# AE8SUPERSET_CM55_HP_View register map
Vendor: Alif Semiconductor; Series: E8; File version: 1.0
CPU: CM55 r1p0, selectable endian, MPU, FPU, double-precision FPU, DSP, VTOR, 8 interrupt priority bits, 1 SAU regions
Registers are 32-bit, read-write, reset 0x0 unless marked. A register's access mark holds for its fields unless they carry their own. Offsets are from the block's base; [hi:lo] are bit positions; lines under a group give offsets from that group; {n}, {i} and the like mark numbered series.

## PINMUX
Base 0x1A603000
{0x0+0x20*i} PINMUX_CFG[{i}] (i=0..17) group
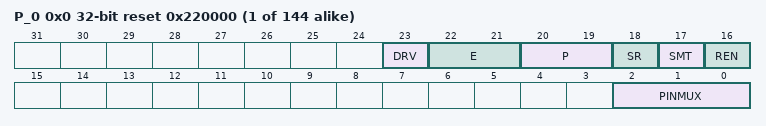
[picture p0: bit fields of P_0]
  {0x0+4j} P_{j} reset 0x220000 (j=0..7) — Control Register for Port n, Pin {j}
    [23] DRV — Driver type
      0=Push-pull; 1=Open drain
    [22:21] E — Output drive strength NOTE: Reset value is 0x3 (12 mA) for registers P4_4, P4_5, P4_6, P4_7
      0=2 mA; 1=4 mA; 2=8 mA; 3=12 mA
    [20:19] P — Driver disabled state control
      0=High-Z; 1=Pull-up; 2=Pull-down; 3=Bus keeper
    [18] SR — Slew rate
      0=Slow; 1=Fast
    [17] SMT — Schmitt trigger (hysteresis) enable
      0=No hysteresis; 1=Hysteresis enabled
    [16] REN — Receiver enable NOTE: Reset value is 0x1 for registers P4_4, P4_5, P4_6, P4_7
      0=Receiver disabled, pin reads return 0; 1=Receiver enabled
    [2:0] PINMUX — Pin multiplexing control field 0x1-0xN: Selects other peripherals as shown in table Pin Function Multiplexing of the device series-specific Datasheet. Un-mapped: Select GPIOn_{j} NOTE: Reset value is 0x1 for registers P4_4, P4_5, P4_6, P4_7
      0=Selects GPIOn_{j} signal from GPIOn peripheral

## VBAT
Base 0x1A609000
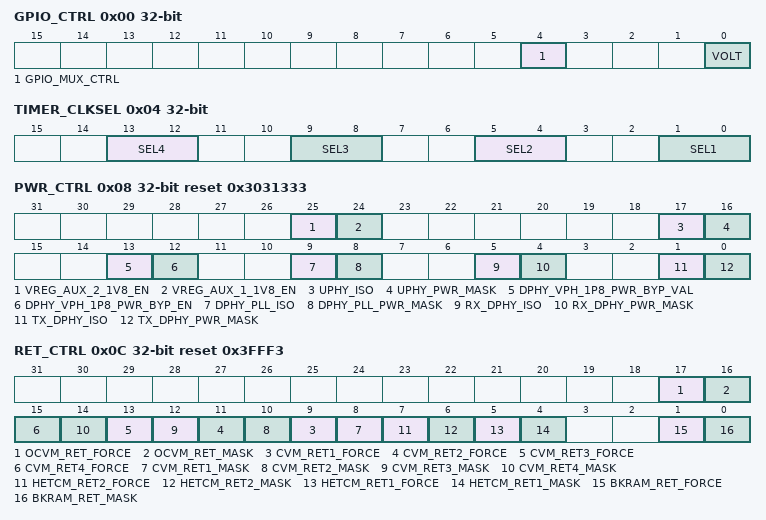
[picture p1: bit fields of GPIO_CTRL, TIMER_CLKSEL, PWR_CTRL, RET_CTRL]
0x00 GPIO_CTRL — GPIO 1.8 V / 3.3 V Power Control Register
  [4] GPIO_MUX_CTRL — Select which LPGPIO controller has access to the GPIOV_* pins
    0=LPGPIO controls the GPIOV_* pins; 1=LPGPIO_FAST controls the GPIOV_* pins
  [0] VOLT — Select voltage level for the 1.8-V/3.3-V (flex) I/O pins
    0=I/O pin will be used with a 3.3-V power; 1=I/O pin will be used with a 1.8-V power
0x04 TIMER_CLKSEL — LPTIMER Clock Select Register
  [13:12] SEL4 — LPTIMER3 clock select
    0=S32K_CLK; 1=128K_CLK (128 kHz); 2=External clock from LPTMR3_CLK_IO pin; 3=LPTIMER2 toggle output (LPTMR2_OUT)
  [9:8] SEL3 — LPTIMER2 clock select
    0=S32K_CLK; 1=128K_CLK (128 kHz); 2=External clock from LPTMR2_CLK_IO pin; 3=S32K_CLK
  [5:4] SEL2 — LPTIMER1 clock select
    0=S32K_CLK; 1=128K_CLK (128 kHz); 2=External clock from LPTMR1_CLK_IO pin; 3=LPTIMER0 toggle output (LPTMR0_OUT)
  [1:0] SEL1 — LPTIMER0 clock select
    0=S32K_CLK; 1=128K_CLK (128 kHz); 2=External clock from LPTMR0_CLK_IO pin; 3=S32K_CLK
0x08 PWR_CTRL reset 0x3031333 — Power Control Register
  [25] VREG_AUX_2_1V8_EN — Enable for AUX regulator 2
    0=Disable; 1=Enable
  [24] VREG_AUX_1_1V8_EN — Enable for AUX regulator 1
    0=Disable; 1=Enable
  [17] UPHY_ISO — Enable isolation for USB PHY
    0=Disable; 1=Enable
  [16] UPHY_PWR_MASK — Mask off the power for USB PHY
    0=Power not masked; 1=Power masked off
  [13] DPHY_VPH_1P8_PWR_BYP_VAL
  [12] DPHY_VPH_1P8_PWR_BYP_EN
    0=Disable; 1=Enable
  [9] DPHY_PLL_ISO — Enable isolation for MIPI PLL
    0=Disable; 1=Enable
  [8] DPHY_PLL_PWR_MASK — Mask off the power for MIPI PLL
    0=Power not masked; 1=Power masked off
  [5] RX_DPHY_ISO — Enable isolation for MIPI RX DPHY
    0=Disable; 1=Enable
  [4] RX_DPHY_PWR_MASK — Mask off the power for MIPI RX DPHY
    0=Power not masked; 1=Power masked off
  [1] TX_DPHY_ISO — Enable isolation for MIPI TX DPHY
    0=Disable; 1=Enable
  [0] TX_DPHY_PWR_MASK — Mask off the power for MIPI TX DPHY
    0=Power not masked; 1=Power masked off
0x0C RET_CTRL reset 0x3FFF3 — Memory Retention Control Register
  [17] OCVM_RET_FORCE — Memory retention force for SRAM1 RET
    0=Force enabling the memory retention; 1=No force
  [16] OCVM_RET_MASK — Memory retention force for SRAM1 RET
    0=No mask; 1=Disable the memory retention
  [2n+7] CVM_RET{n}_FORCE (n=1..4) — Memory retention force for SRAM0 RET{n}
    0=Force enabling the memory retention; 1=No force
  [2n+6] CVM_RET{n}_MASK (n=1..4) — Memory retention force for SRAM0 RET{n}
    0=No mask; 1=Disable the memory retention
  [7] HETCM_RET2_FORCE — Memory retention force for M55-HE TCM RET2
    0=Force enabling the memory retention; 1=No force
  [6] HETCM_RET2_MASK — Memory retention mask for M55-HE TCM RET2
    0=No mask; 1=Disable the memory retention
  [5] HETCM_RET1_FORCE — Memory retention force for M55-HE TCM RET1
    0=Force enabling the memory retention; 1=No force
  [4] HETCM_RET1_MASK — Memory retention mask for M55-HE TCM RET1
    0=No mask; 1=Disable the memory retention
  [1] BKRAM_RET_FORCE — Memory retention force for Utility SRAM
    0=Force enabling the memory retention; 1=No force
  [0] BKRAM_RET_MASK — Memory retention mask for Utility SRAM
    0=No mask; 1=Disable the memory retention
0x10 RTC_CLK_EN — LPRTC Clock Enable Register
  [0] CLK_EN — Enable SYST_PCLK and S32K_CLK for LPRTC. This bit must be set before any programming to LPRTC.
    0=Disable LPRTC clocks; 1=Enable LPRTC clocks
